VERSION "VCU Master demo - Zitto_MB_V1"

NS_ :

BS_:

BU_: BMS MCU VCU DASH

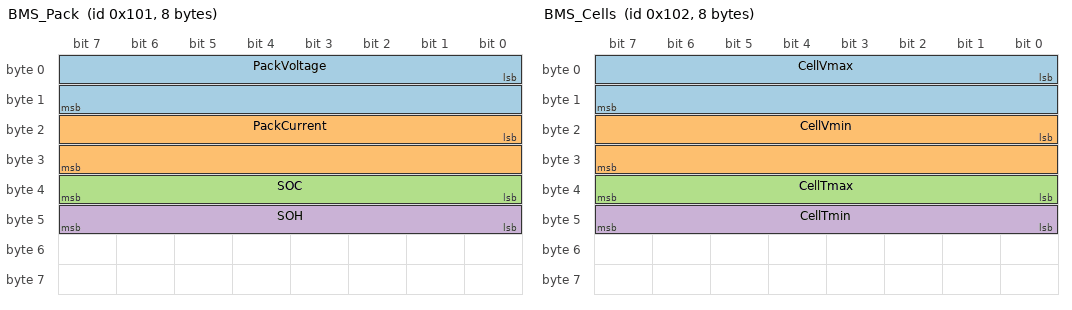
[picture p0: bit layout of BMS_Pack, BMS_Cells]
BO_ 257 BMS_Pack: 8 BMS
 SG_ PackVoltage : 0|16@1+ (0.01,0) [0|100] "V" VCU
 SG_ PackCurrent : 16|16@1- (0.1,0) [-500|500] "A" VCU
 SG_ SOC : 32|8@1+ (0.5,0) [0|100] "%" VCU,DASH
 SG_ SOH : 40|8@1+ (1,0) [0|100] "%" VCU

BO_ 258 BMS_Cells: 8 BMS
 SG_ CellVmax : 0|16@1+ (0.001,0) [0|5] "V" VCU
 SG_ CellVmin : 16|16@1+ (0.001,0) [0|5] "V" VCU
 SG_ CellTmax : 32|8@1+ (1,-40) [-40|125] "degC" VCU
 SG_ CellTmin : 40|8@1+ (1,-40) [-40|125] "degC" VCU

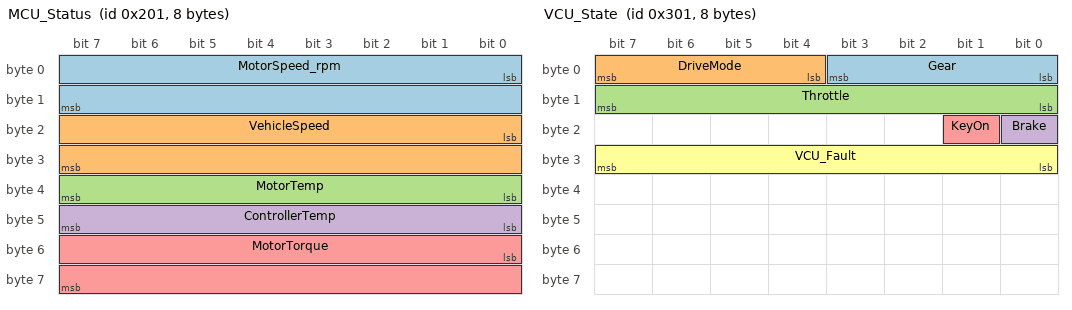
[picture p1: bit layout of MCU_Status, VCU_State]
BO_ 513 MCU_Status: 8 MCU
 SG_ MotorSpeed_rpm : 0|16@1+ (1,0) [0|12000] "rpm" VCU
 SG_ VehicleSpeed : 16|16@1+ (0.01,0) [0|200] "km/h" VCU,DASH
 SG_ MotorTemp : 32|8@1+ (1,-40) [-40|200] "degC" VCU
 SG_ ControllerTemp : 40|8@1+ (1,-40) [-40|200] "degC" VCU
 SG_ MotorTorque : 48|16@1- (0.1,0) [-300|300] "Nm" VCU

BO_ 769 VCU_State: 8 VCU
 SG_ Gear : 0|4@1+ (1,0) [0|15] "" MCU,DASH
 SG_ DriveMode : 4|4@1+ (1,0) [0|15] "" MCU,DASH
 SG_ Throttle : 8|8@1+ (1,0) [0|100] "%" MCU
 SG_ Brake : 16|1@1+ (1,0) [0|1] "" MCU,DASH
 SG_ KeyOn : 17|1@1+ (1,0) [0|1] "" DASH
 SG_ VCU_Fault : 24|8@1+ (1,0) [0|255] "" DASH

BO_ 2566869008 Dash_Odometer: 8 DASH
 SG_ Odometer : 0|32@1+ (0.1,0) [0|429496729] "km" VCU
 SG_ TripA : 32|16@1+ (0.1,0) [0|6553] "km" VCU

CM_ BO_ 257 "Pack level measurements, 20 Hz";
CM_ SG_ 257 SOC "State of charge from coulomb counter";
CM_ BO_ 513 "Motor controller status, 20 Hz";
CM_ BO_ 769 "VCU drive state, CAN2 body bus";

VAL_ 769 Gear 0 "P" 1 "D" 2 "R" 3 "N" ;
VAL_ 769 DriveMode 0 "ECO" 1 "NORMAL" 2 "SPORT" ;
VAL_ 769 Brake 0 "Released" 1 "Pressed" ;
VAL_ 769 KeyOn 0 "Off" 1 "On" ;
VAL_ 769 VCU_Fault 0 "No fault" 1 "Over-current" 2 "Over-temp" 3 "Under-voltage" 4 "CAN timeout" ;
